VERSION ""

BS_:

BU_:

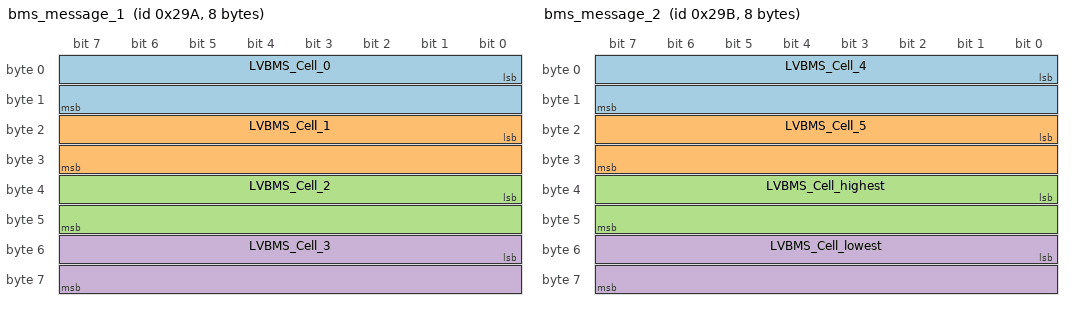
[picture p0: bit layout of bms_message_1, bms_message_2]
BO_ 666 bms_message_1: 8 LVBMS
SG_ LVBMS_Cell_0 : 0|16@1+ (0.001,0) [0|6.5535] "V" LVBMS
SG_ LVBMS_Cell_1 : 16|16@1+ (0.001,0) [0|6.5535] "V" LVBMS
SG_ LVBMS_Cell_2 : 32|16@1+ (0.001,0) [0|6.5535] "V" LVBMS
SG_ LVBMS_Cell_3 : 48|16@1+ (0.001,0) [0|6.5535] "V" LVBMS

BO_ 667 bms_message_2: 8 LVBMS
SG_ LVBMS_Cell_4 : 0|16@1+ (0.001,0) [0|6.5535] "V" LVBMS
SG_ LVBMS_Cell_5 : 16|16@1+ (0.001,0) [0|6.5535] "V" LVBMS
SG_ LVBMS_Cell_highest : 32|16@1+ (0.001,0) [0|6.5535] "V" LVBMS
SG_ LVBMS_Cell_lowest : 48|16@1+ (0.001,0) [0|6.5535] "V" LVBMS

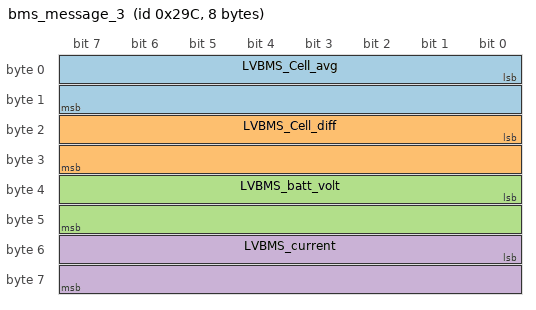
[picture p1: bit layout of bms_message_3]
BO_ 668 bms_message_3: 8 LVBMS
SG_ LVBMS_Cell_avg : 0|16@1+ (0.001,0) [0|6.5535] "V" LVBMS
SG_ LVBMS_Cell_diff : 16|16@1+ (0.001,0) [0|6.5535] "V" LVBMS
SG_ LVBMS_batt_volt : 32|16@1+ (0.001,0) [0|6.5535] "V" LVBMS
SG_ LVBMS_current : 48|16@1+ (0.001,0) [0|8] "A" LVBMS

BO_ 669 bms_message_4: 8 LVBMS
SG_ LVBMS_Thermistor : 0|8@1+ (0.001,0) [0|99] "C" LVBMS
SG_ LVBMS_Status_Short_Circuit : 8|1@1- (1,0) [0|1] " " LVBMS
SG_ LVBMS_Status_Over_Load : 9|1@1- (1,0) [0|1] " " LVBMS
SG_ LVBMS_Status_Over_Voltage : 10|1@1- (1,0) [0|1] " " LVBMS
SG_ LVBMS_Status_Under_Voltage : 11|1@1- (1,0) [0|1] " " LVBMS
SG_ LVBMS_Status_Over_Temp : 12|1@1- (1,0) [0|1] " " LVBMS
SG_ LVBMS_Status_Power_Good : 13|1@1- (1,0) [0|1] " " LVBMS
SG_ LVBMS_Status_Discharging : 14|1@1- (1,0) [0|1] " " LVBMS
SG_ LVBMS_Status_Charging : 15|1@1- (1,0) [0|1] " " LVBMS
SG_ LVBMS_batt_state_standby : 16|1@1- (1,0) [0|1] " " LVBMS
SG_ LVBMS_batt_state_fault : 17|1@1- (1,0) [0|1] " " LVBMS
SG_ LVBMS_batt_state_charging_and_balancing : 18|1@1- (1,0) [0|1] " " LVBMS
SG_ LVBMS_batt_state_charging : 19|1@1- (1,0) [0|1] " " LVBMS
SG_ LVBMS_batt_state_discharging : 20|1@1- (1,0) [0|1] " " LVBMS
SG_ LVBMS_batt_state_balancing : 21|1@1- (1,0) [0|1] " " LVBMS
SG_ LVBMS_batt_xx : 22|1@1- (1,0) [0|1] " " LVBMS
SG_ LVBMS_batt_xxx : 23|1@1- (1,0) [0|1] " " LVBMS
SG_ LVBMS_Balancing_Cell_0 : 24|1@1- (1,0) [0|1] " " LVBMS
SG_ LVBMS_Balancing_Cell_1 : 25|1@1- (1,0) [0|1] " " LVBMS
SG_ LVBMS_Balancing_Cell_2 : 26|1@1- (1,0) [0|1] " " LVBMS
SG_ LVBMS_Balancing_Cell_3 : 27|1@1- (1,0) [0|1] " " LVBMS
SG_ LVBMS_Balancing_Cell_4 : 28|1@1- (1,0) [0|1] " " LVBMS
SG_ LVBMS_Balancing_Cell_5 : 29|1@1- (1,0) [0|1] " " LVBMS
SG_ LVBMS_time_since_fault : 32|8@1+ (1,0) [0|60] "minute" LVBMS
SG_ LVBMS_time_since_balancing : 40|8@1+ (1,0) [0|255] "minute" LVBMS
SG_ LVBMS_time_since_fault_sec : 48|8@1+ (1,0) [0|255] "sec" LVBMS
